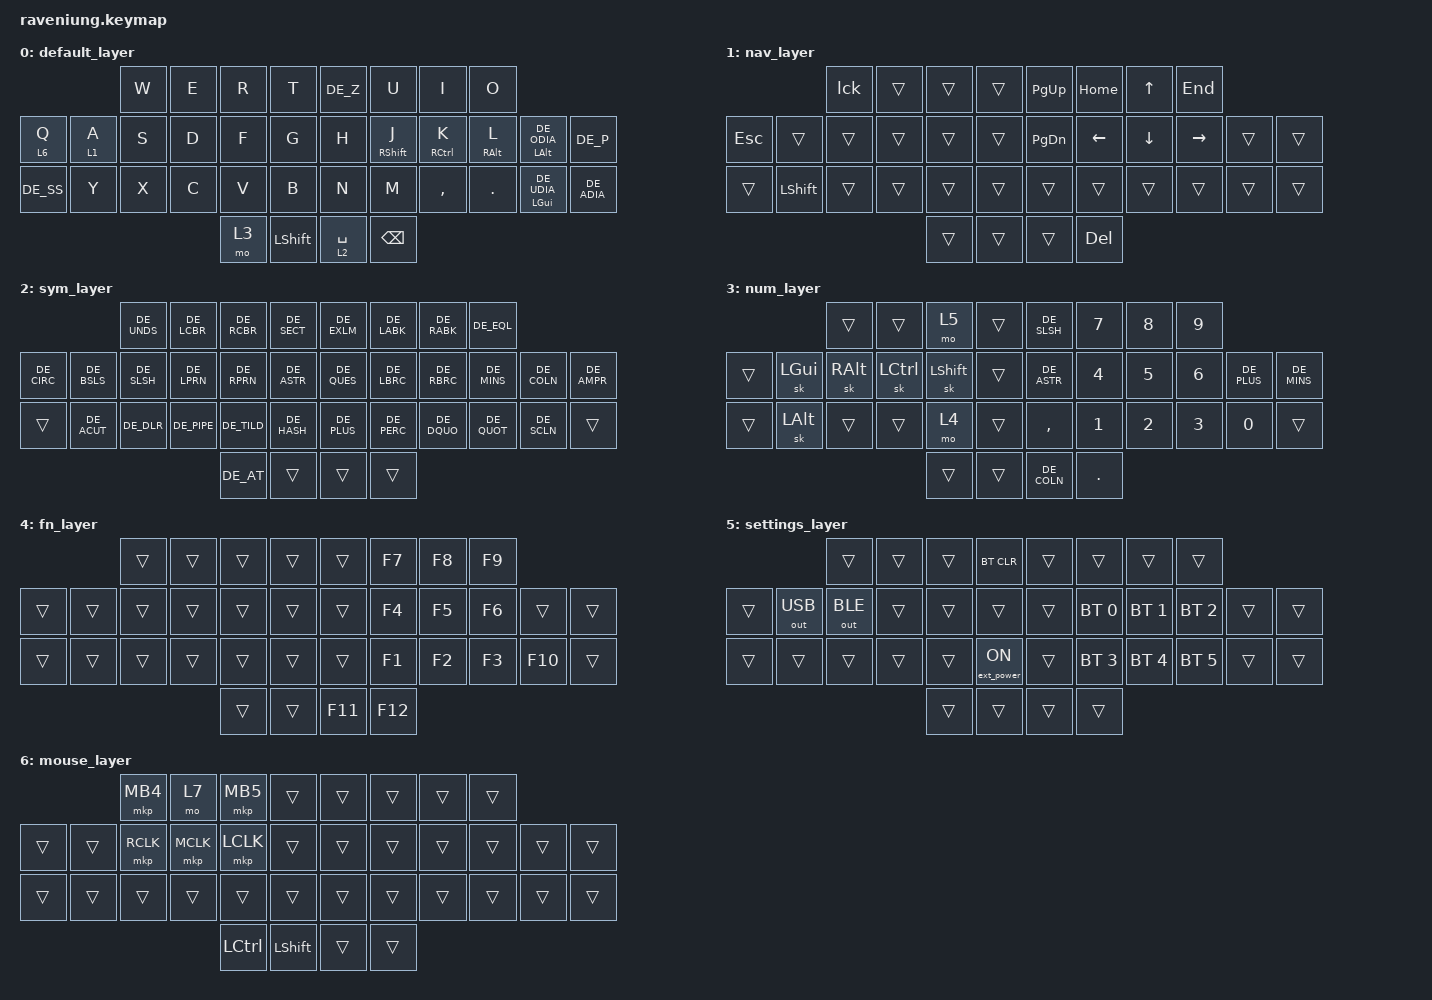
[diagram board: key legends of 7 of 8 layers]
/*
 * Copyright (c) 2020 The ZMK Contributors
 *
 * SPDX-License-Identifier: MIT
 */

#include <dt-bindings/zmk/input_transform.h>
#include <input/processors.dtsi>
#include "keymap_german.h"
#include <behaviors.dtsi>
#include <dt-bindings/zmk/bt.h>
#include <dt-bindings/zmk/ext_power.h>
#include <dt-bindings/zmk/keys.h>
#include <dt-bindings/zmk/outputs.h>
#include <dt-bindings/zmk/pointing.h>

&sk { release-after-ms = <3000>; };

/ {
    keymap {
        compatible = "zmk,keymap";

        default_layer {
            bindings = <
                    &kp W  &kp E  &kp R  &kp T        &kp DE_Z     &kp U         &kp I        &kp O
&lt 6 Q    &lt 1 A  &kp S  &kp D  &kp F  &kp G        &kp H        &hm RSHIFT J  &hm RCTRL K  &hm RALT L  &hm LALT DE_ODIA  &kp DE_P
&kp DE_SS  &kp Y    &kp X  &kp C  &kp V  &kp B        &kp N        &kp M         &kp COMMA    &kp DOT     &hm LGUI DE_UDIA  &kp DE_ADIA
                                  &mo 3  &kp LSHFT    &lt 2 SPACE  &kp BSPC
            >;
        };

        nav_layer {
            bindings = <
                    &lck    &trans  &trans  &trans    &kp PG_UP  &kp HOME  &kp UP    &kp END
&kp ESC  &trans     &trans  &trans  &trans  &trans    &kp PG_DN  &kp LEFT  &kp DOWN  &kp RIGHT  &trans  &trans
&trans   &kp LSHFT  &trans  &trans  &trans  &trans    &trans     &trans    &trans    &trans     &trans  &trans
                                    &trans  &trans    &trans     &kp DEL
            >;
        };

        sym_layer {
            bindings = <
                          &kp DE_UNDS  &kp DE_LCBR  &kp DE_RCBR  &kp DE_SECT    &kp DE_EXLM  &kp DE_LABK  &kp DE_RABK  &kp DE_EQL
&kp DE_CIRC  &kp DE_BSLS  &kp DE_SLSH  &kp DE_LPRN  &kp DE_RPRN  &kp DE_ASTR    &kp DE_QUES  &kp DE_LBRC  &kp DE_RBRC  &kp DE_MINS  &kp DE_COLN  &kp DE_AMPR
&trans       &kp DE_ACUT  &kp DE_DLR   &kp DE_PIPE  &kp DE_TILD  &kp DE_HASH    &kp DE_PLUS  &kp DE_PERC  &kp DE_DQUO  &kp DE_QUOT  &kp DE_SCLN  &trans
                                                    &kp DE_AT    &trans         &trans       &trans
            >;
        };

        num_layer {
            bindings = <
                  &trans    &trans     &mo 5       &trans    &kp DE_SLSH  &kp N7   &kp N8  &kp N9
&trans  &sk LGUI  &sk RALT  &sk LCTRL  &sk LSHIFT  &trans    &kp DE_ASTR  &kp N4   &kp N5  &kp N6  &kp DE_PLUS  &kp DE_MINS
&trans  &sk LALT  &trans    &trans     &mo 4       &trans    &kp COMMA    &kp N1   &kp N2  &kp N3  &kp N0       &trans
                                       &trans      &trans    &kp DE_COLN  &kp DOT
            >;
        };

        fn_layer {
            bindings = <
                &trans  &trans  &trans  &trans    &trans   &kp F7   &kp F8  &kp F9
&trans  &trans  &trans  &trans  &trans  &trans    &trans   &kp F4   &kp F5  &kp F6  &trans   &trans
&trans  &trans  &trans  &trans  &trans  &trans    &trans   &kp F1   &kp F2  &kp F3  &kp F10  &trans
                                &trans  &trans    &kp F11  &kp F12
            >;
        };

        settings_layer {
            bindings = <
                      &trans        &trans  &trans  &bt BT_CLR          &trans  &trans        &trans        &trans
&trans  &out OUT_USB  &out OUT_BLE  &trans  &trans  &trans              &trans  &bt BT_SEL 0  &bt BT_SEL 1  &bt BT_SEL 2  &trans  &trans
&trans  &trans        &trans        &trans  &trans  &ext_power EP_ON    &trans  &bt BT_SEL 3  &bt BT_SEL 4  &bt BT_SEL 5  &trans  &trans
                                            &trans  &trans              &trans  &trans
            >;
        };

        mouse_layer {
            bindings = <
                &mkp MB4   &mo 7      &mkp MB5   &trans       &trans  &trans  &trans  &trans
&trans  &trans  &mkp RCLK  &mkp MCLK  &mkp LCLK  &trans       &trans  &trans  &trans  &trans  &trans  &trans
&trans  &trans  &trans     &trans     &trans     &trans       &trans  &trans  &trans  &trans  &trans  &trans
                                      &kp LCTRL  &kp LSHFT    &trans  &trans
            >;
        };

        scroll_and_media_layer {
            bindings = <
                &trans  &trans  &trans  &trans    &trans  &kp C_PREV      &kp C_PP      &kp C_NEXT
&trans  &trans  &trans  &trans  &trans  &trans    &trans  &kp C_MUTE      &kp C_VOL_DN  &kp C_VOL_UP  &trans  &trans
&trans  &trans  &trans  &trans  &trans  &trans    &trans  &kp C_BRI_AUTO  &kp C_BRI_DN  &kp C_BRI_UP  &trans  &trans
            >;
        };
    };
};
